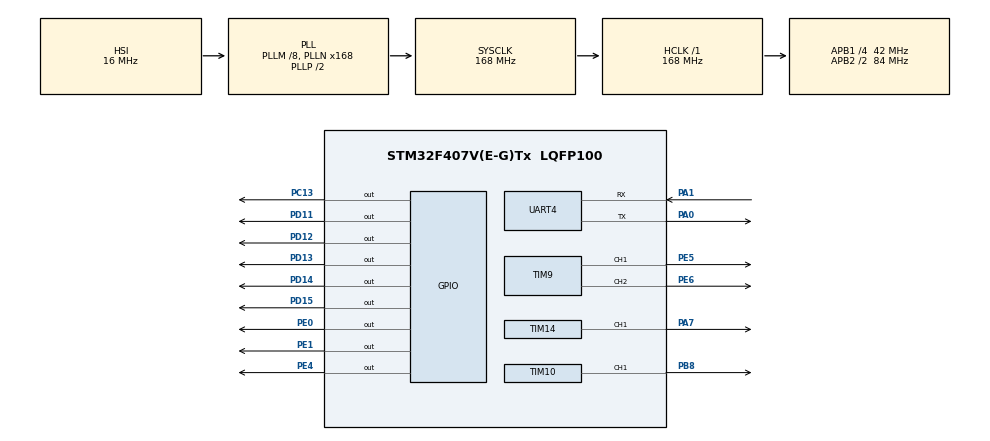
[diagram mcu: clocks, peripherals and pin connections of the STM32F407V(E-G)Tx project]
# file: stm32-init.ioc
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Dma.Request0=UART4_RX
Dma.UART4_RX.0.Direction=DMA_PERIPH_TO_MEMORY
Dma.UART4_RX.0.FIFOMode=DMA_FIFOMODE_DISABLE
Dma.UART4_RX.0.Instance=DMA1_Stream2
Dma.UART4_RX.0.MemDataAlignment=DMA_MDATAALIGN_BYTE
Dma.UART4_RX.0.MemInc=DMA_MINC_ENABLE
Dma.UART4_RX.0.Mode=DMA_NORMAL
Dma.UART4_RX.0.PeriphDataAlignment=DMA_PDATAALIGN_BYTE
Dma.UART4_RX.0.PeriphInc=DMA_PINC_DISABLE
Dma.UART4_RX.0.Priority=DMA_PRIORITY_LOW
Mcu.Family=STM32F4
Mcu.Name=STM32F407V(E-G)Tx
Mcu.Package=LQFP100
NVIC.DMA1_Stream2_IRQn=true\:0\:0\:false\:false\:true\:false\:true\:true
NVIC.PriorityGroup=NVIC_PRIORITYGROUP_0
NVIC.UART4_IRQn=true\:0\:0\:false\:false\:true\:true\:true\:true
PA0-WKUP.Mode=Asynchronous
PA0-WKUP.Signal=UART4_TX
PA1.Mode=Asynchronous
PA1.Signal=UART4_RX
PA13.Mode=Serial_Wire
PA13.Signal=SYS_JTMS-SWDIO
PA14.Mode=Serial_Wire
PA14.Signal=SYS_JTCK-SWCLK
PA7.Signal=S_TIM14_CH1
PB8.Signal=S_TIM10_CH1
PC13-ANTI_TAMP.Signal=GPIO_Output
PC14-OSC32_IN.Mode=LSE-External-Oscillator
PC14-OSC32_IN.Signal=RCC_OSC32_IN
PC15-OSC32_OUT.Mode=LSE-External-Oscillator
PC15-OSC32_OUT.Signal=RCC_OSC32_OUT
PD11.Signal=GPIO_Output
PD12.Signal=GPIO_Output
PD13.Signal=GPIO_Output
PD14.Signal=GPIO_Output
PD15.Signal=GPIO_Output
PE0.Signal=GPIO_Output
PE1.Signal=GPIO_Output
PE4.Signal=GPIO_Output
PE5.Signal=S_TIM9_CH1
PE6.Signal=S_TIM9_CH2
PH0-OSC_IN.Mode=HSE-External-Oscillator
PH0-OSC_IN.Signal=RCC_OSC_IN
PH1-OSC_OUT.Mode=HSE-External-Oscillator
PH1-OSC_OUT.Signal=RCC_OSC_OUT
ProjectManager.HeapSize=0x200
ProjectManager.StackSize=0x400
ProjectManager.TargetToolchain=Makefile
RCC.48MHZClocksFreq_Value=48000000
RCC.AHBFreq_Value=168000000
RCC.APB1CLKDivider=RCC_HCLK_DIV4
RCC.APB1Freq_Value=42000000
RCC.APB1TimFreq_Value=84000000
RCC.APB2CLKDivider=RCC_HCLK_DIV2
RCC.APB2Freq_Value=84000000
RCC.APB2TimFreq_Value=168000000
RCC.CortexFreq_Value=168000000
RCC.HCLKFreq_Value=168000000
RCC.HSE_VALUE=8000000
RCC.HSI_VALUE=16000000
RCC.PLLM=8
RCC.PLLN=168
RCC.PLLQ=7
RCC.SYSCLKFreq_VALUE=168000000
RCC.SYSCLKSource=RCC_SYSCLKSOURCE_PLLCLK
RCC.VCOOutputFreq_Value=336000000
SH.S_TIM10_CH1.0=TIM10_CH1,PWM Generation1 CH1
SH.S_TIM14_CH1.0=TIM14_CH1,PWM Generation1 CH1
SH.S_TIM9_CH1.0=TIM9_CH1,PWM Generation1 CH1
SH.S_TIM9_CH2.0=TIM9_CH2,PWM Generation2 CH2
TIM10.AutoReloadPreload=TIM_AUTORELOAD_PRELOAD_ENABLE
TIM10.Channel=TIM_CHANNEL_1
TIM14.AutoReloadPreload=TIM_AUTORELOAD_PRELOAD_ENABLE
TIM14.Channel=TIM_CHANNEL_1
TIM9.AutoReloadPreload=TIM_AUTORELOAD_PRELOAD_ENABLE
TIM9.Channel-PWM\ Generation1\ CH1=TIM_CHANNEL_1
TIM9.Channel-PWM\ Generation2\ CH2=TIM_CHANNEL_2
UART4.VirtualMode=Asynchronous
VP_TIM10_VS_ClockSourceINT.Mode=Enable_Timer
VP_TIM14_VS_ClockSourceINT.Mode=Enable_Timer
VP_TIM9_VS_ClockSourceINT.Mode=Internal
board=STM32F407G-DISC1

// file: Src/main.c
/* USER CODE BEGIN Header */
/**
  ******************************************************************************
  * @file           : main.c
  * @brief          : Main program body
  ******************************************************************************
  * @attention
  *
  * Copyright (c) 2023 STMicroelectronics.
  * All rights reserved.
  *
  * This software is licensed under terms that can be found in the LICENSE file
  * in the root directory of this software component.
  * If no LICENSE file comes with this software, it is provided AS-IS.
  *
  ******************************************************************************
  */
/* USER CODE END Header */
#include "main.h"
#include "dma.h"
#include "tim.h"
#include "usart.h"
#include "gpio.h"

/* USER CODE BEGIN Includes */
#include "robot.h"
#include "stm32f4xx.h"
#include "stm32f4xx_hal_gpio.h"
#include "stm32f4xx_hal_tim.h"

/* USER CODE END Includes */

void SystemClock_Config(void);

int main(void)
{

  /* MCU Configuration--------------------------------------------------------*/

  /* Reset of all peripherals, Initializes the Flash interface and the Systick. */
  HAL_Init();

  /* Configure the system clock */
  SystemClock_Config();

  /* Initialize all configured peripherals */
  MX_GPIO_Init();
  MX_DMA_Init();
  MX_TIM9_Init();
  MX_TIM10_Init();
  MX_TIM14_Init();
  MX_UART4_Init();
  /* USER CODE BEGIN 2 */

  init_robot();
  operate_robot();

  /* USER CODE END 2 */

  /* Infinite loop */
  while (1)
  {

  }
}

void SystemClock_Config(void)
{
  RCC_OscInitTypeDef RCC_OscInitStruct = {0};
  RCC_ClkInitTypeDef RCC_ClkInitStruct = {0};

  /** Configure the main internal regulator output voltage
  */
  __HAL_RCC_PWR_CLK_ENABLE();
  __HAL_PWR_VOLTAGESCALING_CONFIG(PWR_REGULATOR_VOLTAGE_SCALE1);

  /** Initializes the RCC Oscillators according to the specified parameters
  * in the RCC_OscInitTypeDef structure.
  */
  RCC_OscInitStruct.OscillatorType = RCC_OSCILLATORTYPE_HSI;
  RCC_OscInitStruct.HSIState = RCC_HSI_ON;
  RCC_OscInitStruct.HSICalibrationValue = RCC_HSICALIBRATION_DEFAULT;
  RCC_OscInitStruct.PLL.PLLState = RCC_PLL_ON;
  RCC_OscInitStruct.PLL.PLLSource = RCC_PLLSOURCE_HSI;
  RCC_OscInitStruct.PLL.PLLM = 8;
  RCC_OscInitStruct.PLL.PLLN = 168;
  RCC_OscInitStruct.PLL.PLLP = RCC_PLLP_DIV2;
  RCC_OscInitStruct.PLL.PLLQ = 7;
  if (HAL_RCC_OscConfig(&RCC_OscInitStruct) != HAL_OK)
  {
    Error_Handler();
  }

  /** Initializes the CPU, AHB and APB buses clocks
  */
  RCC_ClkInitStruct.ClockType = RCC_CLOCKTYPE_HCLK|RCC_CLOCKTYPE_SYSCLK
                              |RCC_CLOCKTYPE_PCLK1|RCC_CLOCKTYPE_PCLK2;
  RCC_ClkInitStruct.SYSCLKSource = RCC_SYSCLKSOURCE_PLLCLK;
  RCC_ClkInitStruct.AHBCLKDivider = RCC_SYSCLK_DIV1;
  RCC_ClkInitStruct.APB1CLKDivider = RCC_HCLK_DIV4;
  RCC_ClkInitStruct.APB2CLKDivider = RCC_HCLK_DIV2;

  if (HAL_RCC_ClockConfig(&RCC_ClkInitStruct, FLASH_LATENCY_5) != HAL_OK)
  {
    Error_Handler();
  }
}

void Error_Handler(void)
{
  __disable_irq();
  while (1)
  {
  }
}
